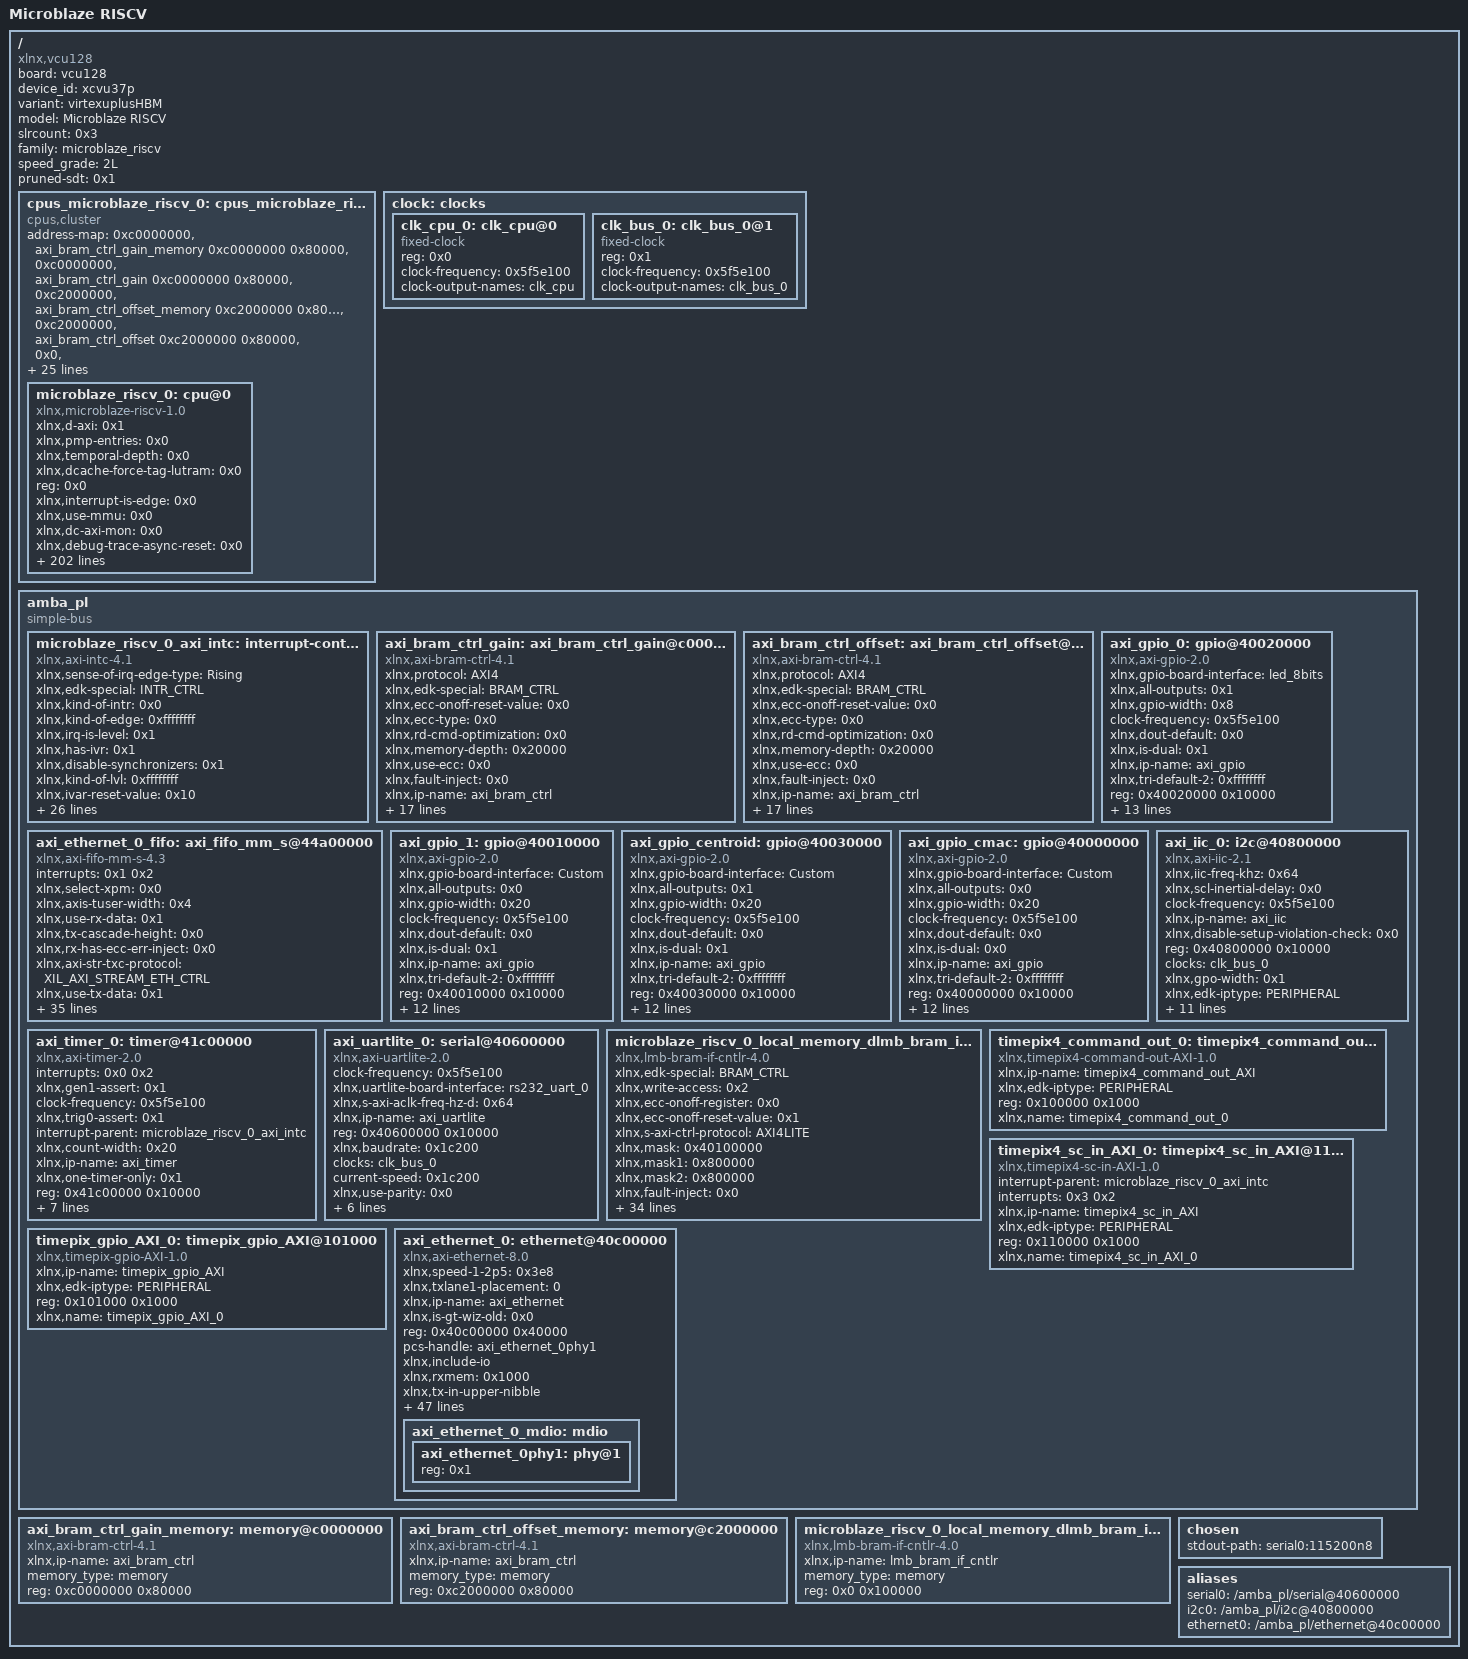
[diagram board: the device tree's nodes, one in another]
/dts-v1/;
/ {
        board = "vcu128";
        compatible = "xlnx,vcu128";
        device_id = "xcvu37p";
        #address-cells = <0x1>;
        variant = "virtexuplusHBM";
        model = "Microblaze RISCV";
        #size-cells = <0x1>;
        slrcount = <0x3>;
        family = "microblaze_riscv";
        speed_grade = "2L";
        pruned-sdt = <0x1>;

        cpus_microblaze_riscv_0: cpus_microblaze_riscv@0 {
                phandle = <0x17>;
                #cpu-mask-cells = <0x1>;
                compatible = "cpus,cluster";
                #address-cells = <0x1>;
                #size-cells = <0x0>;
                address-map = <0xc0000000 &axi_bram_ctrl_gain_memory 0xc0000000 0x80000>,
                 <0xc0000000 &axi_bram_ctrl_gain 0xc0000000 0x80000>,
                 <0xc2000000 &axi_bram_ctrl_offset_memory 0xc2000000 0x80000>,
                 <0xc2000000 &axi_bram_ctrl_offset 0xc2000000 0x80000>,
                 <0x0 &microblaze_riscv_0_local_memory_dlmb_bram_if_cntlr_memory 0x0 0x100000>,
                 <0x0 &microblaze_riscv_0_local_memory_dlmb_bram_if_cntlr 0x0 0x100000>,
                 <0x100000 &timepix4_command_out_0 0x100000 0x1000>,
                 <0x101000 &timepix_gpio_AXI_0 0x101000 0x1000>,
                 <0x110000 &timepix4_sc_in_AXI_0 0x110000 0x1000>,
                 <0x40000000 &axi_gpio_cmac 0x40000000 0x10000>,
                 <0x40010000 &axi_gpio_1 0x40010000 0x10000>,
                 <0x40020000 &axi_gpio_0 0x40020000 0x10000>,
                 <0x40030000 &axi_gpio_centroid 0x40030000 0x10000>,
                 <0x40600000 &axi_uartlite_0 0x40600000 0x10000>,
                 <0x40800000 &axi_iic_0 0x40800000 0x10000>,
                 <0x40c00000 &axi_ethernet_0 0x40c00000 0x40000>,
                 <0x41200000 &microblaze_riscv_0_axi_intc 0x41200000 0x10000>,
                 <0x41c00000 &axi_timer_0 0x41c00000 0x10000>,
                 <0x44a00000 &axi_ethernet_0_fifo 0x44a00000 0x10000>;
                #ranges-address-cells = <0x1>;
                #ranges-size-cells = <0x1>;

                microblaze_riscv_0: cpu@0 {
                        phandle = <0x18>;
                        xlnx,d-axi = <0x1>;
                        xlnx,pmp-entries = <0x0>;
                        xlnx,temporal-depth = <0x0>;
                        xlnx,dcache-force-tag-lutram = <0x0>;
                        reg = <0x0>;
                        xlnx,interrupt-is-edge = <0x0>;
                        xlnx,use-mmu = <0x0>;
                        xlnx,dc-axi-mon = <0x0>;
                        xlnx,debug-trace-async-reset = <0x0>;
                        xlnx,part = "xcvu37p-fsvh2892-2l-e";
                        xlnx,use-config-reset = <0x0>;
                        xlnx,family = "virtexuplusHBM";
                        xlnx,use-sleep = <0x0>;
                        xlnx,d-lmb = <0x1>;
                        xlnx,enable-discrete-ports = <0x0>;
                        xlnx,debug-interface = <0x0>;
                        xlnx,use-ext-brk = <0x0>;
                        xlnx,debug-enabled = <0x1>;
                        xlnx,daddr-size = <0x20>;
                        xlnx,use-extended-fsl-instr = <0x0>;
                        xlnx,branch-target-cache-size = <0x0>;
                        bus-handle = <&amba_pl>;
                        xlnx,pmp-addr0 = <0x0>;
                        xlnx,pmp-addr1 = <0x0>;
                        xlnx,pmp-addr2 = <0x0>;
                        xlnx,pmp-addr3 = <0x0>;
                        xlnx,pmp-addr4 = <0x0>;
                        xlnx,edk-special = "microblaze_riscv";
                        xlnx,use-dcache = <0x0>;
                        xlnx,pmp-addr5 = <0x0>;
                        xlnx,use-muldiv = <0x2>;
                        xlnx,pmp-addr6 = <0x0>;
                        xlnx,use-axi-dp-ext-addr = <0x0>;
                        xlnx,pmp-addr7 = <0x0>;
                        xlnx,pmp-addr8 = <0x0>;
                        xlnx,pmp-addr9 = <0x0>;
                        xlnx,i-axi = <0x0>;
                        xlnx,icache-streams = <0x0>;
                        xlnx,i-lmb-has-prot = <0x0>;
                        xlnx,num-sync-ff-dbg-clk = <0x1>;
                        xlnx,icache-byte-size = <0x1000>;
                        xlnx,pmp-addr10 = <0x0>;
                        d-cache-size = <0x1000>;
                        xlnx,pmp-addr11 = <0x0>;
                        xlnx,pmp-addr12 = <0x0>;
                        xlnx,pmp-addr13 = <0x0>;
                        xlnx,pmp-addr14 = <0x0>;
                        xlnx,pmp-addr15 = <0x0>;
                        xlnx,avoid-primitives = <0x0>;
                        xlnx,pmp-addr16 = <0x0>;
                        xlnx,pmp-addr17 = <0x0>;
                        xlnx,pmp-addr18 = <0x0>;
                        xlnx,pdaddr-size = <0x20>;
                        xlnx,pmp-addr19 = <0x0>;
                        xlnx,pmp-addr20 = <0x0>;
                        xlnx,pmp-addr21 = <0x0>;
                        xlnx,i-lmb = <0x1>;
                        xlnx,pmp-addr22 = <0x0>;
                        xlnx,lmb-data-size = <0x20>;
                        xlnx,lockstep-select = <0x0>;
                        xlnx,pmp-addr23 = <0x0>;
                        timebase-frequency = <0x5f5e100>;
                        xlnx,pmp-addr24 = <0x0>;
                        xlnx,dcache-data-width = <0x0>;
                        xlnx,icache-force-tag-lutram = <0x0>;
                        xlnx,pmp-addr25 = <0x0>;
                        xlnx,pmp-addr26 = <0x0>;
                        xlnx,use-branch-target-cache = <0x0>;
                        xlnx,pmp-addr27 = <0x0>;
                        xlnx,number-of-pc-brk = <0x1>;
                        xlnx,pmp-addr28 = <0x0>;
                        xlnx,imprecise-exceptions = <0x0>;
                        xlnx,pmp-addr29 = <0x0>;
                        xlnx,pmp-addr30 = <0x0>;
                        xlnx,pmp-addr31 = <0x0>;
                        xlnx,pmp-addr32 = <0x0>;
                        model = "microblaze_riscv,1.0";
                        xlnx,pmp-addr33 = <0x0>;
                        xlnx,pmp-addr34 = <0x0>;
                        xlnx,pmp-addr35 = <0x0>;
                        xlnx,pmp-addr36 = <0x0>;
                        d-cache-highaddr = <0x3fffffff>;
                        xlnx,optimization = <0x1>;
                        xlnx,pmp-addr37 = <0x0>;
                        xlnx,pmp-addr38 = <0x0>;
                        xlnx,pmp-addr39 = <0x0>;
                        xlnx,pmp-addr40 = <0x0>;
                        xlnx,pmp-addr41 = <0x0>;
                        xlnx,d-lmb-mon = <0x0>;
                        xlnx,pmp-addr42 = <0x0>;
                        xlnx,pmp-addr43 = <0x0>;
                        xlnx,pmp-addr44 = <0x0>;
                        xlnx,pmp-addr45 = <0x0>;
                        xlnx,pmp-addr46 = <0x0>;
                        xlnx,pmp-addr47 = <0x0>;
                        xlnx,pmp-addr48 = <0x0>;
                        xlnx,fault-tolerant = <0x0>;
                        xlnx,pmp-addr49 = <0x0>;
                        xlnx,pmp-addr50 = <0x0>;
                        xlnx,pmp-addr51 = <0x0>;
                        xlnx,pmp-enhancements = <0x0>;
                        d-cache-line-size = <0x10>;
                        xlnx,mmu-privileged-instr = <0x0>;
                        xlnx,pmp-addr52 = <0x0>;
                        clock-frequency = <0x5f5e100>;
                        xlnx,pmp-addr53 = <0x0>;
                        xlnx,pmp-addr54 = <0x0>;
                        xlnx,pmp-addr55 = <0x0>;
                        xlnx,i-lmb-protocol = <0x0>;
                        xlnx,pmp-addr56 = <0x0>;
                        xlnx,pmp-addr57 = <0x0>;
                        xlnx,dp-axi-mon = <0x0>;
                        xlnx,pmp-addr58 = <0x0>;
                        xlnx,pmp-addr59 = <0x0>;
                        xlnx,pmp-addr60 = <0x0>;
                        xlnx,pmp-addr61 = <0x0>;
                        xlnx,pmp-addr62 = <0x0>;
                        xlnx,pmp-addr63 = <0x0>;
                        xlnx,debug-external-trace = <0x0>;
                        xlnx,addr-size = <0x20>;
                        xlnx,debug-num-progbuf = <0x2>;
                        xlnx,debug-event-counters = <0x0>;
                        xlnx,edk-iptype = "PROCESSOR";
                        xlnx,debug-latency-counters = <0x0>;
                        xlnx,interconnect = <0x2>;
                        xlnx,edge-is-positive = <0x1>;
                        xlnx,use-icache = <0x0>;
                        xlnx,async-wakeup = <0x3>;
                        xlnx,s-axi = <0x0>;
                        xlnx,use-ext-nm-brk = <0x0>;
                        xlnx,ic-axi-mon = <0x0>;
                        xlnx,archid = <0x1>;
                        xlnx,num-sync-ff-clk-irq = <0x1>;
                        xlnx,freq = <0x5f5e100>;
                        xlnx,lockstep-master = <0x0>;
                        xlnx,pmp-cfg0 = <0x0>;
                        xlnx,pmp-cfg1 = <0x0>;
                        xlnx,iaddr-size = <0x20>;
                        xlnx,interrupt-mon = <0x0>;
                        xlnx,pmp-cfg2 = <0x0>;
                        xlnx,number-of-wr-addr-brk = <0x0>;
                        xlnx,pmp-cfg3 = <0x0>;
                        xlnx,pmp-cfg4 = <0x0>;
                        xlnx,use-interrupt = <0x2>;
                        xlnx,pmp-cfg5 = <0x0>;
                        xlnx,async-interrupt = <0x1>;
                        xlnx,pc-width = <0x14>;
                        xlnx,pmp-cfg6 = <0x0>;
                        xlnx,icache-victims = <0x0>;
                        xlnx,pmp-cfg7 = <0x0>;
                        xlnx,pmp-cfg8 = <0x0>;
                        xlnx,pmp-cfg9 = <0x0>;
                        xlnx,use-bitman-a = <0x0>;
                        xlnx,use-bitman-b = <0x0>;
                        xlnx,use-bitman-c = <0x0>;
                        xlnx,i-lmb-mon = <0x0>;
                        xlnx,dcache-byte-size = <0x1000>;
                        xlnx,data-size = <0x20>;
                        compatible = "xlnx,microblaze-riscv-1.0", "xlnx,microblaze_riscv";
                        xlnx,pmp-debug-inhibit = <0x0>;
                        xlnx,use-sstc = <0x1>;
                        xlnx,fsl-exception = <0x0>;
                        xlnx,dcache-use-writeback = <0x0>;
                        device_type = "cpu";
                        xlnx,impid = <0x1>;
                        xlnx,use-bitman-s = <0x0>;
                        xlnx,base-vectors = <0x0>;
                        xlnx,icache-line-len = <0x4>;
                        xlnx,d-lmb-has-prot = <0x0>;
                        xlnx,use-barrel = <0x1>;
                        xlnx,misaligned-exceptions = <0x0>;
                        xlnx,piaddr-size = <0x20>;
                        xlnx,use-bitman = <0x0>;
                        xlnx,dcache-line-len = <0x4>;
                        xlnx,num-sync-ff-clk = <0x2>;
                        xlnx,memory-ip-list = "microblaze_riscv_0_local_memory_ilmb_bram_if_cntlr_memory", "microblaze_riscv_0_local_memory_dlmb_bram_if_cntlr_memory";
                        xlnx,number-of-rd-addr-brk = <0x0>;
                        xlnx,use-counters = <0x1>;
                        xlnx,lockstep-slave = <0x0>;
                        interrupt-handle = <&microblaze_riscv_0_axi_intc>;
                        xlnx,pmp-cfg10 = <0x0>;
                        xlnx,pmp-cfg11 = <0x0>;
                        xlnx,debug-profile-size = <0x0>;
                        xlnx,pmp-cfg12 = <0x0>;
                        xlnx,pmp-cfg13 = <0x0>;
                        xlnx,pmp-cfg14 = <0x0>;
                        xlnx,pmp-cfg15 = <0x0>;
                        xlnx,debug-counter-width = <0x40>;
                        xlnx,icache-data-width = <0x0>;
                        xlnx,ip-name = "microblaze_riscv";
                        xlnx,ip-axi-mon = <0x0>;
                        xlnx,d-lmb-protocol = <0x0>;
                        xlnx,trace = <0x0>;
                        xlnx,ill-instr-exception = <0x1>;
                        xlnx,debug-trace-size = <0x2000>;
                        xlnx,pmp-granularity = <0x3>;
                        xlnx,num-sync-ff-dbg-trace-clk = <0x2>;
                        xlnx,ecc-use-ce-exception = <0x0>;
                        xlnx,num-sync-ff-clk-debug = <0x2>;
                        xlnx,use-atomic = <0x0>;
                        xlnx,g-template-list = <0x1>;
                        xlnx,trap-enhancement = <0x0>;
                        xlnx,hartid = <0x0>;
                        xlnx,use-fpu = <0x0>;
                        xlnx,use-non-secure = <0x0>;
                        d-cache-baseaddr = <0x0>;
                        xlnx,use-compression = <0x1>;
                        xlnx,instr-size = <0x20>;
                        xlnx,fsl-links = <0x0>;
                        xlnx,dcache-victims = <0x0>;
                        xlnx,pmp-read-only = <0x0>;
                };
        };

        clock: clocks {
                phandle = <0x19>;
                #address-cells = <0x1>;
                #size-cells = <0x0>;

                clk_cpu_0: clk_cpu@0 {
                        phandle = <0x1a>;
                        compatible = "fixed-clock";
                        reg = <0x0>;
                        clock-frequency = <0x5f5e100>;
                        clock-output-names = "clk_cpu";
                        #clock-cells = <0x0>;
                };

                clk_bus_0: clk_bus_0@1 {
                        phandle = <0x15>;
                        compatible = "fixed-clock";
                        reg = <0x1>;
                        clock-frequency = <0x5f5e100>;
                        clock-output-names = "clk_bus_0";
                        #clock-cells = <0x0>;
                };
        };

        amba_pl: amba_pl {
                phandle = <0x14>;
                ranges;
                compatible = "simple-bus";
                #address-cells = <0x1>;
                #size-cells = <0x1>;

                microblaze_riscv_0_axi_intc: interrupt-controller@41200000 {
                        phandle = <0x11>;
                        #interrupt-cells = <0x2>;
                        xlnx,sense-of-irq-edge-type = "Rising";
                        xlnx,edk-special = "INTR_CTRL";
                        xlnx,kind-of-intr = <0x0>;
                        xlnx,kind-of-edge = <0xffffffff>;
                        xlnx,irq-is-level = <0x1>;
                        xlnx,has-ivr = <0x1>;
                        compatible = "xlnx,axi-intc-4.1", "xlnx,xps-intc-1.00.a";
                        xlnx,disable-synchronizers = <0x1>;
                        xlnx,kind-of-lvl = <0xffffffff>;
                        xlnx,ivar-reset-value = <0x10>;
                        xlnx,irq-active = <0x1>;
                        xlnx,en-cascade-mode = <0x0>;
                        xlnx,ip-name = "axi_intc";
                        xlnx,has-ilr = <0x0>;
                        reg = <0x41200000 0x10000>;
                        xlnx,addr-width = <0x20>;
                        xlnx,s-axi-aclk-freq-mhz = <0x64>;
                        xlnx,num-sw-intr = <0x0>;
                        xlnx,irq-connection = <0x0>;
                        xlnx,num-intr-inputs = <0x4>;
                        xlnx,has-sie = <0x1>;
                        xlnx,enable-async = <0x0>;
                        xlnx,has-cie = <0x1>;
                        xlnx,num-sync-ff = <0x2>;
                        xlnx,edk-iptype = "PERIPHERAL";
                        xlnx,mb-clk-not-connected = <0x1>;
                        xlnx,has-ipr = <0x1>;
                        xlnx,sense-of-irq-level-type = "Active_High";
                        xlnx,cascade-master = <0x0>;
                        xlnx,processor-clk-freq-mhz = <0x64>;
                        status = "okay";
                        xlnx,is-fast = <0x1>;
                        xlnx,has-fast = <0x1>;
                        xlnx,ivar-rst-val = <0x10>;
                        interrupt-controller;
                        xlnx,async-intr = <0xfffffff4>;
                        xlnx,name = "microblaze_riscv_0_axi_intc";
                };

                axi_bram_ctrl_gain: axi_bram_ctrl_gain@c0000000 {
                        phandle = <0x2>;
                        xlnx,protocol = "AXI4";
                        xlnx,edk-special = "BRAM_CTRL";
                        compatible = "xlnx,axi-bram-ctrl-4.1", "xlnx,axi-bram-ctrl";
                        xlnx,ecc-onoff-reset-value = <0x0>;
                        xlnx,ecc-type = <0x0>;
                        xlnx,rd-cmd-optimization = <0x0>;
                        xlnx,memory-depth = <0x20000>;
                        xlnx,use-ecc = <0x0>;
                        xlnx,fault-inject = <0x0>;
                        xlnx,ip-name = "axi_bram_ctrl";
                        reg = <0xc0000000 0x80000>;
                        xlnx,bmg-instance = "EXTERNAL";
                        xlnx,s-axi-ctrl-addr-width = <0x20>;
                        xlnx,read-latency = <0x1>;
                        xlnx,id-width = <0x0>;
                        xlnx,s-axi-supports-narrow-burst = <0x0>;
                        xlnx,supports-narrow-burst = <0x0>;
                        xlnx,single-port-bram = <0x1>;
                        xlnx,ecc = <0x0>;
                        xlnx,edk-iptype = "PERIPHERAL";
                        status = "okay";
                        xlnx,data-width = <0x20>;
                        xlnx,bram-addr-width = <0x11>;
                        xlnx,bram-inst-mode = "EXTERNAL";
                        xlnx,s-axi-ctrl-data-width = <0x20>;
                        xlnx,mem-depth = <0x20000>;
                        xlnx,s-axi-id-width = <0x1>;
                        xlnx,name = "axi_bram_ctrl_gain";
                };

                axi_bram_ctrl_offset: axi_bram_ctrl_offset@c2000000 {
                        phandle = <0x4>;
                        xlnx,protocol = "AXI4";
                        xlnx,edk-special = "BRAM_CTRL";
                        compatible = "xlnx,axi-bram-ctrl-4.1", "xlnx,axi-bram-ctrl";
                        xlnx,ecc-onoff-reset-value = <0x0>;
                        xlnx,ecc-type = <0x0>;
                        xlnx,rd-cmd-optimization = <0x0>;
                        xlnx,memory-depth = <0x20000>;
                        xlnx,use-ecc = <0x0>;
                        xlnx,fault-inject = <0x0>;
                        xlnx,ip-name = "axi_bram_ctrl";
                        reg = <0xc2000000 0x80000>;
                        xlnx,bmg-instance = "EXTERNAL";
                        xlnx,s-axi-ctrl-addr-width = <0x20>;
                        xlnx,read-latency = <0x1>;
                        xlnx,id-width = <0x0>;
                        xlnx,s-axi-supports-narrow-burst = <0x0>;
                        xlnx,supports-narrow-burst = <0x0>;
                        xlnx,single-port-bram = <0x1>;
                        xlnx,ecc = <0x0>;
                        xlnx,edk-iptype = "PERIPHERAL";
                        status = "okay";
                        xlnx,data-width = <0x20>;
                        xlnx,bram-addr-width = <0x11>;
                        xlnx,bram-inst-mode = "EXTERNAL";
                        xlnx,s-axi-ctrl-data-width = <0x20>;
                        xlnx,mem-depth = <0x20000>;
                        xlnx,s-axi-id-width = <0x1>;
                        xlnx,name = "axi_bram_ctrl_offset";
                };

                axi_ethernet_0_fifo: axi_fifo_mm_s@44a00000 {
                        phandle = <0x13>;
                        interrupts = <0x1 0x2>;
                        xlnx,select-xpm = <0x0>;
                        xlnx,axis-tuser-width = <0x4>;
                        compatible = "xlnx,axi-fifo-mm-s-4.3", "xlnx,axi-fifo-mm-s";
                        xlnx,use-rx-data = <0x1>;
                        xlnx,tx-cascade-height = <0x0>;
                        xlnx,rx-has-ecc-err-inject = <0x0>;
                        xlnx,axi-str-txc-protocol = "XIL_AXI_STREAM_ETH_CTRL";
                        xlnx,use-tx-data = <0x1>;
                        xlnx,tx-has-ecc-err-inject = <0x0>;
                        xlnx,rx-fifo-depth = <0x1000>;
                        interrupt-parent = <&microblaze_riscv_0_axi_intc>;
                        xlnx,has-axis-tuser = <0x0>;
                        xlnx,tx-fifo-depth = <0x1000>;
                        xlnx,rx-fifo-pe-threshold = <0xa>;
                        xlnx,data-interface-type = <0x0>;
                        xlnx,ip-name = "axi_fifo_mm_s";
                        xlnx,use-tx-ctrl = <0x1>;
                        xlnx,rx-fifo-pf-threshold = <0xfa0>;
                        xlnx,axis-tid-width = <0x4>;
                        reg = <0x44a00000 0x10000>;
                        xlnx,tx-fifo-pe-threshold = <0xa>;
                        xlnx,tx-fifo-pf-threshold = <0xfa0>;
                        xlnx,s-axi4-data-width = <0x20>;
                        xlnx,has-axis-tstrb = <0x0>;
                        xlnx,axi-str-rxd-protocol = "XIL_AXI_STREAM_ETH_DATA";
                        xlnx,use-rx-cut-through = <0x0>;
                        xlnx,axi-str-rxd-tdata-width = <0x20>;
                        xlnx,axis-tdest-width = <0x4>;
                        xlnx,edk-iptype = "PERIPHERAL";
                        xlnx,has-axis-tkeep = <0x1>;
                        xlnx,has-axis-tid = <0x0>;
                        xlnx,axi-str-txc-tdata-width = <0x20>;
                        xlnx,axi-str-txd-protocol = "XIL_AXI_STREAM_ETH_DATA";
                        xlnx,use-tx-cut-through = <0x0>;
                        xlnx,axi-str-txd-tdata-width = <0x20>;
                        xlnx,rx-enable-ecc = <0x0>;
                        status = "okay";
                        xlnx,has-axis-tdest = <0x0>;
                        interrupt-names = "interrupt";
                        xlnx,tx-enable-ecc = <0x0>;
                        xlnx,s-axi-id-width = <0x4>;
                        xlnx,rx-cascade-height = <0x0>;
                        xlnx,name = "axi_ethernet_0_fifo";
                };

                axi_gpio_0: gpio@40020000 {
                        phandle = <0xc>;
                        xlnx,gpio-board-interface = "led_8bits";
                        compatible = "xlnx,axi-gpio-2.0", "xlnx,xps-gpio-1.00.a";
                        xlnx,all-outputs = <0x1>;
                        #gpio-cells = <0x2>;
                        xlnx,gpio-width = <0x8>;
                        clock-frequency = <0x5f5e100>;
                        xlnx,dout-default = <0x0>;
                        xlnx,is-dual = <0x1>;
                        xlnx,ip-name = "axi_gpio";
                        xlnx,tri-default-2 = <0xffffffff>;
                        reg = <0x40020000 0x10000>;
                        xlnx,all-inputs-2 = <0x0>;
                        clocks = <&clk_bus_0>;
                        xlnx,all-outputs-2 = <0x1>;
                        gpio-controller;
                        xlnx,interrupt-present = <0x0>;
                        xlnx,gpio2-board-interface = "Custom";
                        xlnx,edk-iptype = "PERIPHERAL";
                        xlnx,dout-default-2 = <0x0>;
                        status = "okay";
                        xlnx,gpio2-width = <0x4>;
                        clock-names = "s_axi_aclk";
                        xlnx,use-board-flow;
                        xlnx,tri-default = <0xffffffff>;
                        xlnx,name = "axi_gpio_0";
                        xlnx,all-inputs = <0x0>;
                };

                axi_gpio_1: gpio@40010000 {
                        phandle = <0xb>;
                        xlnx,gpio-board-interface = "Custom";
                        compatible = "xlnx,axi-gpio-2.0", "xlnx,xps-gpio-1.00.a";
                        xlnx,all-outputs = <0x0>;
                        #gpio-cells = <0x2>;
                        xlnx,gpio-width = <0x20>;
                        clock-frequency = <0x5f5e100>;
                        xlnx,dout-default = <0x0>;
                        xlnx,is-dual = <0x1>;
                        xlnx,ip-name = "axi_gpio";
                        xlnx,tri-default-2 = <0xffffffff>;
                        reg = <0x40010000 0x10000>;
                        xlnx,all-inputs-2 = <0x0>;
                        clocks = <&clk_bus_0>;
                        xlnx,all-outputs-2 = <0x0>;
                        gpio-controller;
                        xlnx,interrupt-present = <0x0>;
                        xlnx,gpio2-board-interface = "Custom";
                        xlnx,edk-iptype = "PERIPHERAL";
                        xlnx,dout-default-2 = <0x0>;
                        status = "okay";
                        xlnx,gpio2-width = <0x20>;
                        clock-names = "s_axi_aclk";
                        xlnx,tri-default = <0xffffffff>;
                        xlnx,name = "axi_gpio_1";
                        xlnx,all-inputs = <0x0>;
                };

                axi_gpio_centroid: gpio@40030000 {
                        phandle = <0xd>;
                        xlnx,gpio-board-interface = "Custom";
                        compatible = "xlnx,axi-gpio-2.0", "xlnx,xps-gpio-1.00.a";
                        xlnx,all-outputs = <0x1>;
                        #gpio-cells = <0x2>;
                        xlnx,gpio-width = <0x20>;
                        clock-frequency = <0x5f5e100>;
                        xlnx,dout-default = <0x0>;
                        xlnx,is-dual = <0x1>;
                        xlnx,ip-name = "axi_gpio";
                        xlnx,tri-default-2 = <0xffffffff>;
                        reg = <0x40030000 0x10000>;
                        xlnx,all-inputs-2 = <0x0>;
                        clocks = <&clk_bus_0>;
                        xlnx,all-outputs-2 = <0x1>;
                        gpio-controller;
                        xlnx,interrupt-present = <0x0>;
                        xlnx,gpio2-board-interface = "Custom";
                        xlnx,edk-iptype = "PERIPHERAL";
                        xlnx,dout-default-2 = <0x0>;
                        status = "okay";
                        xlnx,gpio2-width = <0x20>;
                        clock-names = "s_axi_aclk";
                        xlnx,tri-default = <0xffffffff>;
                        xlnx,name = "axi_gpio_centroid";
                        xlnx,all-inputs = <0x0>;
                };

                axi_gpio_cmac: gpio@40000000 {
                        phandle = <0xa>;
                        xlnx,gpio-board-interface = "Custom";
                        compatible = "xlnx,axi-gpio-2.0", "xlnx,xps-gpio-1.00.a";
                        xlnx,all-outputs = <0x0>;
                        #gpio-cells = <0x2>;
                        xlnx,gpio-width = <0x20>;
                        clock-frequency = <0x5f5e100>;
                        xlnx,dout-default = <0x0>;
                        xlnx,is-dual = <0x0>;
                        xlnx,ip-name = "axi_gpio";
                        xlnx,tri-default-2 = <0xffffffff>;
                        reg = <0x40000000 0x10000>;
                        xlnx,all-inputs-2 = <0x0>;
                        clocks = <&clk_bus_0>;
                        xlnx,all-outputs-2 = <0x0>;
                        gpio-controller;
                        xlnx,interrupt-present = <0x0>;
                        xlnx,gpio2-board-interface = "Custom";
                        xlnx,edk-iptype = "PERIPHERAL";
                        xlnx,dout-default-2 = <0x0>;
                        status = "okay";
                        xlnx,gpio2-width = <0x20>;
                        clock-names = "s_axi_aclk";
                        xlnx,tri-default = <0xffffffff>;
                        xlnx,name = "axi_gpio_cmac";
                        xlnx,all-inputs = <0x0>;
                };

                axi_iic_0: i2c@40800000 {
                        phandle = <0xf>;
                        xlnx,iic-freq-khz = <0x64>;
                        compatible = "xlnx,axi-iic-2.1", "xlnx,xps-iic-2.00.a";
                        xlnx,scl-inertial-delay = <0x0>;
                        clock-frequency = <0x5f5e100>;
                        xlnx,ip-name = "axi_iic";
                        xlnx,disable-setup-violation-check = <0x0>;
                        reg = <0x40800000 0x10000>;
                        clocks = <&clk_bus_0>;
                        xlnx,gpo-width = <0x1>;
                        xlnx,edk-iptype = "PERIPHERAL";
                        xlnx,static-timing-reg-width = <0x0>;
                        xlnx,sda-level = <0x1>;
                        status = "okay";
                        xlnx,ten-bit-adr = <0x0>;
                        xlnx,default-value = <0x0>;
                        xlnx,iic-board-interface = "Custom";
                        xlnx,timing-reg-width = <0x20>;
                        xlnx,iic-freq = <0x186a0>;
                        xlnx,smbus-pmbus-host = <0x0>;
                        xlnx,name = "axi_iic_0";
                        xlnx,axi-aclk-freq-mhz = <0x64>;
                        xlnx,sda-inertial-delay = <0x0>;
                };

                axi_timer_0: timer@41c00000 {
                        phandle = <0x12>;
                        interrupts = <0x0 0x2>;
                        compatible = "xlnx,axi-timer-2.0", "xlnx,xps-timer-1.00.a";
                        xlnx,gen1-assert = <0x1>;
                        clock-frequency = <0x5f5e100>;
                        xlnx,trig0-assert = <0x1>;
                        interrupt-parent = <&microblaze_riscv_0_axi_intc>;
                        xlnx,count-width = <0x20>;
                        xlnx,ip-name = "axi_timer";
                        xlnx,one-timer-only = <0x1>;
                        reg = <0x41c00000 0x10000>;
                        clocks = <&clk_bus_0>;
                        xlnx,gen0-assert = <0x1>;
                        xlnx,mode-64bit = <0x0>;
                        xlnx,edk-iptype = "PERIPHERAL";
                        status = "okay";
                        xlnx,trig1-assert = <0x1>;
                        xlnx,enable-timer2 = <0x0>;
                        interrupt-names = "interrupt";
                        xlnx,name = "axi_timer_0";
                };

                axi_uartlite_0: serial@40600000 {
                        phandle = <0xe>;
                        compatible = "xlnx,axi-uartlite-2.0", "xlnx,xps-uartlite-1.00.a";
                        clock-frequency = <0x5f5e100>;
                        xlnx,uartlite-board-interface = "rs232_uart_0";
                        xlnx,s-axi-aclk-freq-hz-d = <0x64>;
                        xlnx,ip-name = "axi_uartlite";
                        reg = <0x40600000 0x10000>;
                        xlnx,baudrate = <0x1c200>;
                        clocks = <&clk_bus_0>;
                        current-speed = <0x1c200>;
                        xlnx,use-parity = <0x0>;
                        xlnx,edk-iptype = "PERIPHERAL";
                        xlnx,odd-parity = <0x0>;
                        status = "okay";
                        xlnx,use-board-flow;
                        xlnx,name = "axi_uartlite_0";
                        xlnx,data-bits = <0x8>;
                        xlnx,parity = "No_Parity";
                };

                microblaze_riscv_0_local_memory_dlmb_bram_if_cntlr: lmb_bram_if_cntlr@0 {
                        phandle = <0x6>;
                        xlnx,edk-special = "BRAM_CTRL";
                        xlnx,write-access = <0x2>;
                        compatible = "xlnx,lmb-bram-if-cntlr-4.0", "xlnx,axi-bram-ctrl";
                        xlnx,ecc-onoff-register = <0x0>;
                        xlnx,ecc-onoff-reset-value = <0x1>;
                        xlnx,s-axi-ctrl-protocol = "AXI4LITE";
                        xlnx,mask = <0x40100000>;
                        xlnx,mask1 = <0x800000>;
                        xlnx,mask2 = <0x800000>;
                        xlnx,fault-inject = <0x0>;
                        xlnx,mask3 = <0x800000>;
                        xlnx,ip-name = "lmb_bram_if_cntlr";
                        xlnx,arbitration = <0x0>;
                        xlnx,num-lmb = <0x1>;
                        xlnx,mask4 = <0x800000>;
                        reg = <0x0 0x100000>;
                        xlnx,s-axi-ctrl-addr-width = <0x20>;
                        xlnx,mask5 = <0x800000>;
                        xlnx,ecc-status-registers = <0x0>;
                        xlnx,prot-cfg = <0xff>;
                        xlnx,mask6 = <0x800000>;
                        xlnx,lmb-protocol = <0x0>;
                        xlnx,ce-counter-width = <0x0>;
                        xlnx,prot-cfg1 = <0xff>;
                        xlnx,mask7 = <0x800000>;
                        xlnx,ecc = <0x0>;
                        xlnx,edk-iptype = "PERIPHERAL";
                        xlnx,prot-cfg2 = <0xff>;
                        xlnx,lmb-dwidth = <0x20>;
                        xlnx,interconnect = <0x0>;
                        xlnx,ce-failing-registers = <0x0>;
                        xlnx,prot-cfg3 = <0xff>;
                        xlnx,ue-failing-registers = <0x0>;
                        xlnx,prot-cfg4 = <0xff>;
                        xlnx,lmb-has-prot = <0x0>;
                        status = "okay";
                        xlnx,data-width = <0x20>;
                        xlnx,prot-cfg5 = <0xff>;
                        xlnx,s-axi-ctrl-data-width = <0x20>;
                        xlnx,prot-cfg6 = <0xff>;
                        xlnx,bram-awidth = <0x20>;
                        xlnx,prot-cfg7 = <0xff>;
                        xlnx,lmb-awidth = <0x20>;
                        xlnx,name = "microblaze_riscv_0_local_memory_dlmb_bram_if_cntlr";
                };

                timepix4_command_out_0: timepix4_command_out_AXI@100000 {
                        phandle = <0x7>;
                        compatible = "xlnx,timepix4-command-out-AXI-1.0";
                        status = "okay";
                        xlnx,ip-name = "timepix4_command_out_AXI";
                        xlnx,edk-iptype = "PERIPHERAL";
                        reg = <0x100000 0x1000>;
                        xlnx,name = "timepix4_command_out_0";
                };

                timepix4_sc_in_AXI_0: timepix4_sc_in_AXI@110000 {
                        phandle = <0x9>;
                        interrupt-parent = <&microblaze_riscv_0_axi_intc>;
                        interrupts = <0x3 0x2>;
                        compatible = "xlnx,timepix4-sc-in-AXI-1.0";
                        status = "okay";
                        xlnx,ip-name = "timepix4_sc_in_AXI";
                        interrupt-names = "sc_irq";
                        xlnx,edk-iptype = "PERIPHERAL";
                        reg = <0x110000 0x1000>;
                        xlnx,name = "timepix4_sc_in_AXI_0";
                };

                timepix_gpio_AXI_0: timepix_gpio_AXI@101000 {
                        phandle = <0x8>;
                        compatible = "xlnx,timepix-gpio-AXI-1.0";
                        status = "okay";
                        xlnx,ip-name = "timepix_gpio_AXI";
                        xlnx,edk-iptype = "PERIPHERAL";
                        reg = <0x101000 0x1000>;
                        xlnx,name = "timepix_gpio_AXI_0";
                };

                axi_ethernet_0: ethernet@40c00000 {
                        phandle = <0x10>;
                        xlnx,speed-1-2p5 = <0x3e8>;
                        xlnx,txlane1-placement = "0";
                        xlnx,ip-name = "axi_ethernet";
                        xlnx,is-gt-wiz-old = <0x0>;
                        reg = <0x40c00000 0x40000>;
                        pcs-handle = <&axi_ethernet_0phy1>;
                        xlnx,include-io;
                        xlnx,rxmem = <0x1000>;
                        xlnx,tx-in-upper-nibble;
                        xlnx,axisclkrate = <0x0>;
                        xlnx,txmem = "0";
                        xlnx,mdio-board-interface = "0";
                        xlnx,phyaddr = <0x1>;
                        xlnx,enable-lvds;
                        xlnx,supportlevel = <0x0>;
                        local-mac-address = [00 0A 23 00 00 00];
                        xlnx,diffclk-board-interface = "0";
                        xlnx,frame-filter;
                        axistream-connected = <&axi_ethernet_0_fifo>;
                        interrupt-names = "interrupt";
                        xlnx,phyrst-board-interface-dummy-port = "0";
                        compatible = "xlnx,axi-ethernet-8.0", "xlnx,axi-ethernet-1.00.a", "xlnx,axi-ethernet-1.00.a";
                        xlnx,gt-type = "0";
                        xlnx,drpclkrate = <0x0>;
                        clock-frequency;
                        axistream-control-connected = <&axi_ethernet_0_fifo>;
                        interrupt-parent = <&microblaze_riscv_0_axi_intc>;
                        managed = "in-band-status";
                        xlnx,versal-gt-board-flow = <0x0>;
                        xlnx,switch-x-sgmii;
                        max-speed = <0x3e8>;
                        status = "okay";
                        xlnx,timer-format = <0x0>;
                        xlnx,use-board-flow;
                        xlnx,statistics-width = "0";
                        xlnx,name = "axi_ethernet_0";
                        interrupts = <0x2 0x2>;
                        xlnx,instantiatebitslice0;
                        xlnx,gtrefclksrc = "0";
                        xlnx,rxcsum = <0x0>;
                        xlnx,statistics-counters;
                        xlnx,edk-iptype = "0";
                        xlnx,gtrefclkrate = <0x0>;
                        xlnx,lvdsclkrate = <0x0>;
                        xlnx,number-of-table-entries = <0x0>;
                        xlnx,rxlane0-placement = "0";
                        xlnx,timer-clk-period = <0x0>;
                        xlnx,ethernet-board-interface = "0";
                        xlnx,txlane0-placement = "0";
                        xlnx,gtlocation = "0";
                        phy-mode = "sgmii";
                        xlnx,gt-settings = <0x0>;
                        xlnx,clockselection = "0";
                        xlnx,processor-mode;
                        xlnx,txcsum = <0x0>;
                        xlnx,phyrst-board-interface = "0";
                        xlnx,axiliteclkrate = <0x0>;
                        xlnx,rxlane1-placement = "0";

                        axi_ethernet_0_mdio: mdio {
                                phandle = <0x1c>;
                                #address-cells = <0x1>;
                                #size-cells = <0x0>;

                                axi_ethernet_0phy1: phy@1 {
                                        phandle = <0x16>;
                                        device_type = "ethernet-phy";
                                        reg = <0x1>;
                                };
                        };
                };
        };

        axi_bram_ctrl_gain_memory: memory@c0000000 {
                phandle = <0x1>;
                compatible = "xlnx,axi-bram-ctrl-4.1";
                xlnx,ip-name = "axi_bram_ctrl";
                device_type = "memory";
                memory_type = "memory";
                reg = <0xc0000000 0x80000>;
        };

        axi_bram_ctrl_offset_memory: memory@c2000000 {
                phandle = <0x3>;
                compatible = "xlnx,axi-bram-ctrl-4.1";
                xlnx,ip-name = "axi_bram_ctrl";
                device_type = "memory";
                memory_type = "memory";
                reg = <0xc2000000 0x80000>;
        };

        microblaze_riscv_0_local_memory_dlmb_bram_if_cntlr_memory: memory@0 {
                phandle = <0x5>;
                compatible = "xlnx,lmb-bram-if-cntlr-4.0";
                xlnx,ip-name = "lmb_bram_if_cntlr";
                device_type = "memory";
                memory_type = "memory";
                reg = <0x0 0x100000>;
        };

        chosen {
                stdout-path = "serial0:115200n8";
        };

        aliases {
                serial0 = "/amba_pl/serial@40600000";
                i2c0 = "/amba_pl/i2c@40800000";
                ethernet0 = "/amba_pl/ethernet@40c00000";
        };

        __symbols__ {
                cpus_microblaze_riscv_0 = "/cpus_microblaze_riscv@0";
                microblaze_riscv_0 = "/cpus_microblaze_riscv@0/cpu@0";
                clock = "/clocks";
                clk_cpu_0 = "/clocks/clk_cpu@0";
                clk_bus_0 = "/clocks/clk_bus_0@1";
                amba_pl = "/amba_pl";
                microblaze_riscv_0_axi_intc = "/amba_pl/interrupt-controller@41200000";
                axi_bram_ctrl_gain = "/amba_pl/axi_bram_ctrl_gain@c0000000";
                axi_bram_ctrl_offset = "/amba_pl/axi_bram_ctrl_offset@c2000000";
                axi_ethernet_0_fifo = "/amba_pl/axi_fifo_mm_s@44a00000";
                axi_gpio_0 = "/amba_pl/gpio@40020000";
                axi_gpio_1 = "/amba_pl/gpio@40010000";
                axi_gpio_centroid = "/amba_pl/gpio@40030000";
                axi_gpio_cmac = "/amba_pl/gpio@40000000";
                axi_iic_0 = "/amba_pl/i2c@40800000";
                axi_timer_0 = "/amba_pl/timer@41c00000";
                axi_uartlite_0 = "/amba_pl/serial@40600000";
                microblaze_riscv_0_local_memory_dlmb_bram_if_cntlr = "/amba_pl/lmb_bram_if_cntlr@0";
                timepix4_command_out_0 = "/amba_pl/timepix4_command_out_AXI@100000";
                timepix4_sc_in_AXI_0 = "/amba_pl/timepix4_sc_in_AXI@110000";
                timepix_gpio_AXI_0 = "/amba_pl/timepix_gpio_AXI@101000";
                axi_ethernet_0 = "/amba_pl/ethernet@40c00000";
                axi_ethernet_0_mdio = "/amba_pl/ethernet@40c00000/mdio";
                axi_ethernet_0phy1 = "/amba_pl/ethernet@40c00000/mdio/phy@1";
                axi_bram_ctrl_gain_memory = "/memory@c0000000";
                axi_bram_ctrl_offset_memory = "/memory@c2000000";
                microblaze_riscv_0_local_memory_dlmb_bram_if_cntlr_memory = "/memory@0";
        };
};
